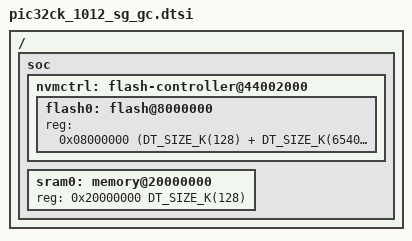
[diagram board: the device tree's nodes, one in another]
/*
 * Copyright (c) 2026 Microchip Technology Inc.
 *
 * SPDX-License-Identifier: Apache-2.0
 */
/ {
	soc {
		nvmctrl: flash-controller@44002000 {
			flash0: flash@8000000 {
				/* Reg size computation:
				 * BFM: 128kB, Unused Region: 65408kB, PFM: 1MB
				 */
				reg = <0x08000000
				       (DT_SIZE_K(128) + DT_SIZE_K(65408) + DT_SIZE_M(1))>;
				#address-cells = <1>;
				#size-cells = <1>;
				ranges = <0x0 0x08000000
					  (DT_SIZE_K(128) + DT_SIZE_K(65408) + DT_SIZE_M(1))>;
			};
		};

		sram0: memory@20000000 {
			reg = <0x20000000 DT_SIZE_K(128)>;
		};
	};
};
